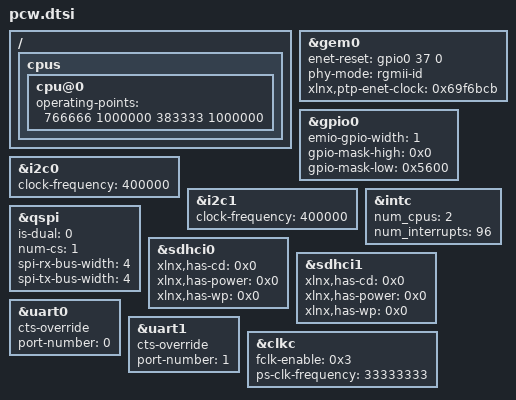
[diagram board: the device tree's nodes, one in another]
/*
 * CAUTION: This file is automatically generated by Xilinx.
 * Version:  
 * Today is: Mon Jan 18 13:38:43 2021
 */


/ {
	cpus {
		cpu@0 {
			operating-points = <766666 1000000 383333 1000000>;
		};
	};
};
&gem0 {
	enet-reset = <&gpio0 37 0>;
	phy-mode = "rgmii-id";
	status = "okay";
	xlnx,ptp-enet-clock = <0x69f6bcb>;
};
&gpio0 {
	emio-gpio-width = <1>;
	gpio-mask-high = <0x0>;
	gpio-mask-low = <0x5600>;
};
&i2c0 {
	clock-frequency = <400000>;
	status = "okay";
};
&i2c1 {
	clock-frequency = <400000>;
	status = "okay";
};
&intc {
	num_cpus = <2>;
	num_interrupts = <96>;
};
&qspi {
	is-dual = <0>;
	num-cs = <1>;
	spi-rx-bus-width = <4>;
	spi-tx-bus-width = <4>;
	status = "okay";
};
&sdhci0 {
	status = "okay";
	xlnx,has-cd = <0x0>;
	xlnx,has-power = <0x0>;
	xlnx,has-wp = <0x0>;
};
&sdhci1 {
	status = "okay";
	xlnx,has-cd = <0x0>;
	xlnx,has-power = <0x0>;
	xlnx,has-wp = <0x0>;
};
&uart0 {
	cts-override ;
	device_type = "serial";
	port-number = <0>;
	status = "okay";
};
&uart1 {
	cts-override ;
	device_type = "serial";
	port-number = <1>;
	status = "okay";
};
&clkc {
	fclk-enable = <0x3>;
	ps-clk-frequency = <33333333>;
};
